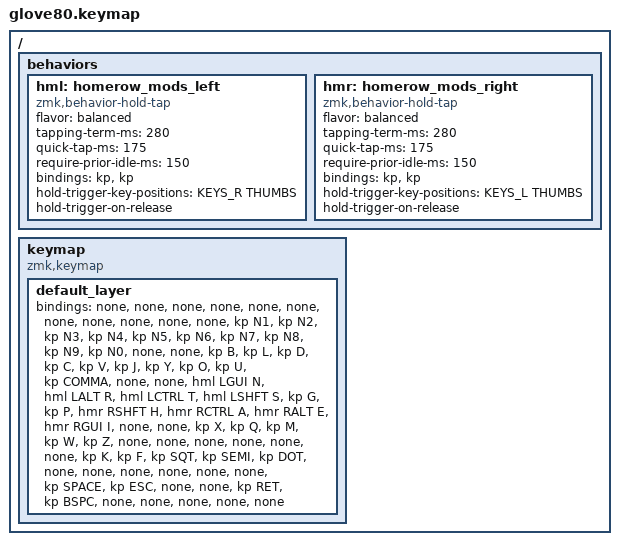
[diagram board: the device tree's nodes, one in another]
/*
 * Copyright (c) 2020 The ZMK Contributors
 *
 * SPDX-License-Identifier: MIT
 */

#include <behaviors.dtsi>
#include <dt-bindings/zmk/keys.h>

#define KEYS_L 0 1 2 3 4 10 11 12 13 14 15 22 23 24 25 26 27 34 35 36 37 38 39 46 47 48 49 50 51 64 65 66 67 68
#define KEYS_R 5 6 7 8 9 16 17 18 19 20 21 28 29 30 31 32 33 40 41 42 43 44 45 58 59 60 61 62 63 75 76 77 78 79
#define THUMBS 52 53 54 55 56 57 69 70 71 72 73 74

/ {
    behaviors {
        hml: homerow_mods_left {
            compatible = "zmk,behavior-hold-tap";
            #binding-cells = <2>;
            flavor = "balanced";
            tapping-term-ms = <280>;
            quick-tap-ms = <175>;
            require-prior-idle-ms = <150>;
            bindings = <&kp>, <&kp>;
            hold-trigger-key-positions = <KEYS_R THUMBS>;
            hold-trigger-on-release;
        };

        hmr: homerow_mods_right {
            compatible = "zmk,behavior-hold-tap";
            #binding-cells = <2>;
            flavor = "balanced";
            tapping-term-ms = <280>;
            quick-tap-ms = <175>;
            require-prior-idle-ms = <150>;
            bindings = <&kp>, <&kp>;
            hold-trigger-key-positions = <KEYS_L THUMBS>;
            hold-trigger-on-release;
        };
    };

    keymap {
        compatible = "zmk,keymap";

        default_layer {
            bindings = <
            &none            // Left edge row, pinky
            &none            // Left edge row, ring
            &none            // Left edge row, middle
            &none            // Left edge row, index
            &none            // Left edge row, inner

            &none            // Right edge row, inner
            &none            // Right edge row, index
            &none            // Right edge row, middle
            &none            // Right edge row, ring
            &none            // Right edge row, pinky

            &none            // Left number row, outer
            &kp N1           // Left number row, pinky
            &kp N2           // Left number row, ring
            &kp N3           // Left number row, middle
            &kp N4           // Left number row, index
            &kp N5           // Left number row, inner

            &kp N6           // Right number row, inner
            &kp N7           // Right number row, index
            &kp N8           // Right number row, middle
            &kp N9           // Right number row, ring
            &kp N0           // Right number row, pinky
            &none            // Right number row, outer

            &none            // Left top row, outer
            &kp B            // Left top row, pinky
            &kp L            // Left top row, ring
            &kp D            // Left top row, middle
            &kp C            // Left top row, index
            &kp V            // Left top row, inner

            &kp J            // Right top row, inner
            &kp Y            // Right top row, index
            &kp O            // Right top row, middle
            &kp U            // Right top row, ring
            &kp COMMA        // Right top row, pinky
            &none            // Right top row, outer

            &none            // Left home row, outer
            &hml LGUI N      // Left home row, pinky
            &hml LALT R      // Left home row, ring
            &hml LCTRL T     // Left home row, middle
            &hml LSHFT S     // Left home row, index
            &kp G            // Left home row, inner

            &kp P            // Right home row, inner
            &hmr RSHFT H     // Right home row, index
            &hmr RCTRL A     // Right home row, middle
            &hmr RALT E      // Right home row, ring
            &hmr RGUI I      // Right home row, pinky
            &none            // Right home row, outer

            &none            // Left bottom row, outer
            &kp X            // Left bottom row, pinky
            &kp Q            // Left bottom row, ring
            &kp M            // Left bottom row, middle
            &kp W            // Left bottom row, index
            &kp Z            // Left bottom row, inner

            &none            // Left upper thumb cluster, inner
            &none            // Left upper thumb cluster, middle
            &none            // Left upper thumb cluster, outer

            &none            // Right upper thumb cluster, outer
            &none            // Right upper thumb cluster, middle
            &none            // Right upper thumb cluster, inner

            &kp K            // Right bottom row, inner
            &kp F            // Right bottom row, index
            &kp SQT          // Right bottom row, middle
            &kp SEMI         // Right bottom row, ring
            &kp DOT          // Right bottom row, pinky
            &none            // Right bottom row, outer

            &none            // Left last row, outer
            &none            // Left last row, pinky
            &none            // Left last row, ring
            &none            // Left last row, middle
            &none            // Left last row, index

            &kp SPACE        // Left lower thumb cluster, inner
            &kp ESC          // Left lower thumb cluster, middle
            &none            // Left lower thumb cluster, outer

            &none            // Right lower thumb cluster, outer
            &kp RET          // Right lower thumb cluster, middle
            &kp BSPC         // Right lower thumb cluster, inner

            &none            // Right last row, index
            &none            // Right last row, middle
            &none            // Right last row, ring
            &none            // Right last row, pinky
            &none            // Right last row, outer
            >;
        };
    };
};
